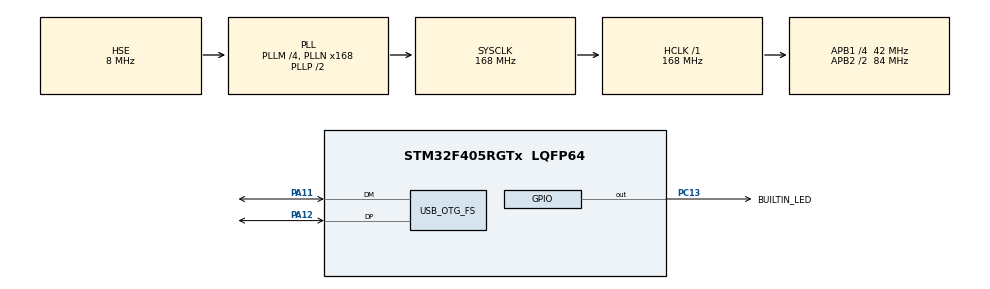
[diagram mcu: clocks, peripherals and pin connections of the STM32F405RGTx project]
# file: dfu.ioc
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Mcu.Family=STM32F4
Mcu.Name=STM32F405RGTx
Mcu.Package=LQFP64
NVIC.OTG_FS_IRQn=true\:0\:0\:false\:false\:true\:false\:true
NVIC.PriorityGroup=NVIC_PRIORITYGROUP_4
NVIC.TIM7_IRQn=true\:0\:0\:false\:false\:true\:true\:true
PA11.Mode=Device_Only
PA11.Signal=USB_OTG_FS_DM
PA12.Mode=Device_Only
PA12.Signal=USB_OTG_FS_DP
PA13.Mode=Serial_Wire
PA13.Signal=SYS_JTMS-SWDIO
PA14.Mode=Serial_Wire
PA14.Signal=SYS_JTCK-SWCLK
PC13-ANTI_TAMP.GPIO_Label=BUILTIN_LED
PC13-ANTI_TAMP.PinState=GPIO_PIN_SET
PC13-ANTI_TAMP.Signal=GPIO_Output
PH0-OSC_IN.Mode=HSE-External-Oscillator
PH0-OSC_IN.Signal=RCC_OSC_IN
PH1-OSC_OUT.Mode=HSE-External-Oscillator
PH1-OSC_OUT.Signal=RCC_OSC_OUT
ProjectManager.HeapSize=0x200
ProjectManager.StackSize=0x400
ProjectManager.TargetToolchain=STM32CubeIDE
RCC.48MHZClocksFreq_Value=48000000
RCC.AHBFreq_Value=168000000
RCC.APB1CLKDivider=RCC_HCLK_DIV4
RCC.APB1Freq_Value=42000000
RCC.APB1TimFreq_Value=84000000
RCC.APB2CLKDivider=RCC_HCLK_DIV2
RCC.APB2Freq_Value=84000000
RCC.APB2TimFreq_Value=168000000
RCC.CortexFreq_Value=168000000
RCC.HCLKFreq_Value=168000000
RCC.HSE_VALUE=8000000
RCC.HSI_VALUE=16000000
RCC.LSE_VALUE=32768
RCC.PLLM=4
RCC.PLLN=168
RCC.PLLQ=7
RCC.SYSCLKFreq_VALUE=168000000
RCC.SYSCLKSource=RCC_SYSCLKSOURCE_PLLCLK
RCC.VCOOutputFreq_Value=336000000
TIM7.Period=4999
TIM7.Prescaler=8399
TIM7.TIM_MasterOutputTrigger=TIM_TRGO_UPDATE
USB_DEVICE.CLASS_NAME_FS=DFU
USB_DEVICE.VirtualMode-DFU_FS=Dfu
USB_DEVICE.VirtualModeFS=Dfu_FS
USB_OTG_FS.VirtualMode=Device_Only
USB_OTG_FS.lpm_enable=DISABLE
VP_TIM7_VS_ClockSourceINT.Mode=Enable_Timer
VP_USB_DEVICE_VS_USB_DEVICE_DFU_FS.Mode=DFU_FS
board=custom

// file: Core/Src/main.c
/* USER CODE BEGIN Header */
/**
  ******************************************************************************
  * @file           : main.c
  * @brief          : Main program body
  ******************************************************************************
  * @attention
  *
  * <h2><center>&copy; Copyright (c) 2020 STMicroelectronics.
  * All rights reserved.</center></h2>
  *
  * This software component is licensed by ST under BSD 3-Clause license,
  * the "License"; You may not use this file except in compliance with the
  * License. You may obtain a copy of the License at:
  *                        opensource.org/licenses/BSD-3-Clause
  *
  ******************************************************************************
  */
/* USER CODE END Header */
#include "main.h"
#include "usb_device.h"

TIM_HandleTypeDef htim7;

void SystemClock_Config(void);
static void MX_GPIO_Init(void);
static void MX_TIM7_Init(void);

/* USER CODE BEGIN 0 */
// Handle built-in blue led hanging off of C13
void HAL_TIM_PeriodElapsedCallback(TIM_HandleTypeDef *htim) {

	if (htim->Instance == TIM7) {
		HAL_GPIO_TogglePin(BUILTIN_LED_GPIO_Port, BUILTIN_LED_Pin);
	}

}
/* USER CODE END 0 */

int main(void)
{

  /* MCU Configuration--------------------------------------------------------*/

  /* Reset of all peripherals, Initializes the Flash interface and the Systick. */
  HAL_Init();

  /* Configure the system clock */
  SystemClock_Config();

  /* Initialize all configured peripherals */
  MX_GPIO_Init();
  MX_TIM7_Init();
  MX_USB_DEVICE_Init();
  /* USER CODE BEGIN 2 */

  HAL_TIM_Base_Start_IT(&htim7);

  /* USER CODE END 2 */

  /* Infinite loop */
  while (1)
  {

  }
}

void SystemClock_Config(void)
{
  RCC_OscInitTypeDef RCC_OscInitStruct = {0};
  RCC_ClkInitTypeDef RCC_ClkInitStruct = {0};

  /** Configure the main internal regulator output voltage
  */
  __HAL_RCC_PWR_CLK_ENABLE();
  __HAL_PWR_VOLTAGESCALING_CONFIG(PWR_REGULATOR_VOLTAGE_SCALE1);
  /** Initializes the RCC Oscillators according to the specified parameters
  * in the RCC_OscInitTypeDef structure.
  */
  RCC_OscInitStruct.OscillatorType = RCC_OSCILLATORTYPE_HSE;
  RCC_OscInitStruct.HSEState = RCC_HSE_ON;
  RCC_OscInitStruct.PLL.PLLState = RCC_PLL_ON;
  RCC_OscInitStruct.PLL.PLLSource = RCC_PLLSOURCE_HSE;
  RCC_OscInitStruct.PLL.PLLM = 4;
  RCC_OscInitStruct.PLL.PLLN = 168;
  RCC_OscInitStruct.PLL.PLLP = RCC_PLLP_DIV2;
  RCC_OscInitStruct.PLL.PLLQ = 7;
  if (HAL_RCC_OscConfig(&RCC_OscInitStruct) != HAL_OK)
  {
    Error_Handler();
  }
  /** Initializes the CPU, AHB and APB buses clocks
  */
  RCC_ClkInitStruct.ClockType = RCC_CLOCKTYPE_HCLK|RCC_CLOCKTYPE_SYSCLK
                              |RCC_CLOCKTYPE_PCLK1|RCC_CLOCKTYPE_PCLK2;
  RCC_ClkInitStruct.SYSCLKSource = RCC_SYSCLKSOURCE_PLLCLK;
  RCC_ClkInitStruct.AHBCLKDivider = RCC_SYSCLK_DIV1;
  RCC_ClkInitStruct.APB1CLKDivider = RCC_HCLK_DIV4;
  RCC_ClkInitStruct.APB2CLKDivider = RCC_HCLK_DIV2;

  if (HAL_RCC_ClockConfig(&RCC_ClkInitStruct, FLASH_LATENCY_5) != HAL_OK)
  {
    Error_Handler();
  }
}

static void MX_TIM7_Init(void)
{

  TIM_MasterConfigTypeDef sMasterConfig = {0};

  htim7.Instance = TIM7;
  htim7.Init.Prescaler = 8399;
  htim7.Init.CounterMode = TIM_COUNTERMODE_UP;
  htim7.Init.Period = 4999;
  htim7.Init.AutoReloadPreload = TIM_AUTORELOAD_PRELOAD_DISABLE;
  if (HAL_TIM_Base_Init(&htim7) != HAL_OK)
  {
    Error_Handler();
  }
  sMasterConfig.MasterOutputTrigger = TIM_TRGO_UPDATE;
  sMasterConfig.MasterSlaveMode = TIM_MASTERSLAVEMODE_DISABLE;
  if (HAL_TIMEx_MasterConfigSynchronization(&htim7, &sMasterConfig) != HAL_OK)
  {
    Error_Handler();
  }

}

static void MX_GPIO_Init(void)
{
  GPIO_InitTypeDef GPIO_InitStruct = {0};

  /* GPIO Ports Clock Enable */
  __HAL_RCC_GPIOC_CLK_ENABLE();
  __HAL_RCC_GPIOH_CLK_ENABLE();
  __HAL_RCC_GPIOA_CLK_ENABLE();

  /*Configure GPIO pin Output Level */
  HAL_GPIO_WritePin(BUILTIN_LED_GPIO_Port, BUILTIN_LED_Pin, GPIO_PIN_SET);

  /*Configure GPIO pin : BUILTIN_LED_Pin */
  GPIO_InitStruct.Pin = BUILTIN_LED_Pin;
  GPIO_InitStruct.Mode = GPIO_MODE_OUTPUT_PP;
  GPIO_InitStruct.Pull = GPIO_NOPULL;
  GPIO_InitStruct.Speed = GPIO_SPEED_FREQ_LOW;
  HAL_GPIO_Init(BUILTIN_LED_GPIO_Port, &GPIO_InitStruct);

}

void Error_Handler(void)
{
}

/************************ (C) COPYRIGHT STMicroelectronics *****END OF FILE****/
